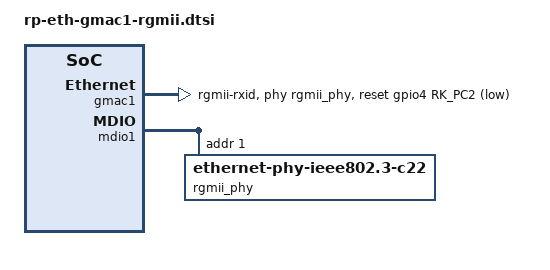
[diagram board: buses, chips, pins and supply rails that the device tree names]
&gmac1 {
        /* Use rgmii-rxid mode to disable rx delay inside Soc */
        phy-mode = "rgmii-rxid";
        clock_in_out = "input";

        snps,reset-gpio = <&gpio4 RK_PC2 GPIO_ACTIVE_LOW>;
        snps,reset-active-low;
        /* Reset time is 20ms, 100ms for rtl8211f */
        snps,reset-delays-us = <0 20000 100000>;

	tx_delay = <0x07>;
        /* rx_delay = <0x3f>; */

        pinctrl-names = "default";
        pinctrl-0 = <&rgmii_miim
                     &rgmii_tx_bus2
                     &rgmii_rx_bus2
                     &rgmii_rgmii_clk
                     &rgmii_rgmii_bus
		     &rgmii_clk
		     &eth_pins>;

        phy-handle = <&rgmii_phy>;
        status = "okay";
};

&mdio1 {
        rgmii_phy: phy@1 {
                compatible = "ethernet-phy-ieee802.3-c22";
                reg = <0x1>;
		clocks = <&cru CLK_GMAC1_VPU_25M>;
        };
};

